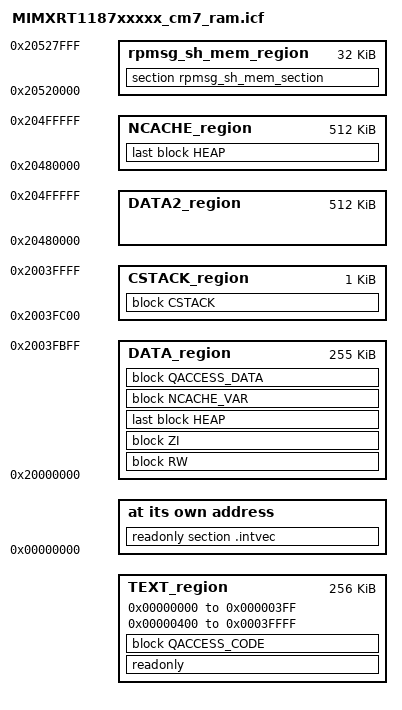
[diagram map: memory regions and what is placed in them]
/*
** ###################################################################
**     Processors:          MIMXRT1187CVM8B_cm7
**
**     Compiler:            IAR ANSI C/C++ Compiler for ARM
**     Reference manual:    IMXRT1180RM, Rev 1, 02/2021
**     Version:             rev. 1.0, 2020-12-29
**     Build:               b210402
**
**     Abstract:
**         Linker file for the IAR ANSI C/C++ Compiler for ARM
**
**     Copyright 2016 Freescale Semiconductor, Inc.
**     Copyright 2016-2021 NXP
**     All rights reserved.
**
**     SPDX-License-Identifier: BSD-3-Clause
**
**     http:                 www.nxp.com
**     mail:                 support@nxp.com
**
** ###################################################################
*/

define symbol vector_table_size        = 0x00000400;

define symbol m_itcm_start             = 0x00000000;
define symbol m_itcm_size              = 0x00040000;

define symbol m_dtcm_start             = 0x20000000;
define symbol m_dtcm_size              = 0x00040000;

define symbol m_ocram1_start           = 0x20480000;
define symbol m_ocram1_size            = 0x00080000;

define symbol m_ocram2_start           = 0x20500000;
define symbol m_ocram2_size            = 0x00020000;

if (isdefinedsymbol(__use_shmem__)) {
  define exported symbol rpmsg_sh_mem_start      = 0x20520000;
  define exported symbol rpmsg_sh_mem_end        = 0x20527FFF;

  define exported symbol __RPMSG_SH_MEM_START    = rpmsg_sh_mem_start;
  define exported symbol __RPMSG_SH_MEM_SIZE     = rpmsg_sh_mem_end - rpmsg_sh_mem_start + 1;
}

/* code & data allocation */
define symbol m_interrupts_start       = m_itcm_start;
define symbol m_interrupts_end         = m_itcm_start + vector_table_size -1;

define symbol m_text_start             = m_itcm_start + vector_table_size;
define symbol m_text_end               = m_itcm_start + m_itcm_size - 1;

define symbol m_data_start             = m_dtcm_start;
define symbol m_data_end               = m_dtcm_start + m_dtcm_size -1;

define symbol m_data2_start            = m_ocram1_start;
define symbol m_data2_end              = m_ocram1_start + m_ocram1_size -1;

define symbol m_ncache_start           = m_ocram1_start;
define symbol m_ncache_end             = m_ocram1_start + m_ocram1_size -1;

define exported symbol __NCACHE_REGION_START   = m_ncache_start;
define exported symbol __NCACHE_REGION_SIZE    = m_ncache_end - m_ncache_start + 1;

/* Sizes */
if (isdefinedsymbol(__stack_size__)) {
  define symbol __size_cstack__        = __stack_size__;
} else {
  define symbol __size_cstack__        = 0x0400;
}

if (isdefinedsymbol(__heap_size__)) {
  define symbol __size_heap__          = __heap_size__;
} else {
  define symbol __size_heap__          = 0x0400;
}

define exported symbol __VECTOR_TABLE          = m_interrupts_start;
define exported symbol __VECTOR_RAM            = m_interrupts_start;
define exported symbol __RAM_VECTOR_TABLE_SIZE = 0x0;

define memory mem with size = 4G;
define region TEXT_region = mem:[from m_interrupts_start to m_interrupts_end]
                          | mem:[from m_text_start to m_text_end];
define region DATA_region = mem:[from m_data_start to m_data_end-__size_cstack__];
define region DATA2_region = mem:[from m_data2_start to m_data2_end];
define region CSTACK_region = mem:[from m_data_end-__size_cstack__+1 to m_data_end];
define region NCACHE_region = mem:[from m_ncache_start to m_ncache_end];
if (isdefinedsymbol(__use_shmem__)) {
  define region rpmsg_sh_mem_region     = mem:[from rpmsg_sh_mem_start to rpmsg_sh_mem_end];
}

define block RW        { readwrite };
define block ZI        { zi };
define block CSTACK    with alignment = 8, size = __size_cstack__   { };
define block HEAP      with alignment = 8, size = __size_heap__     { };
define block NCACHE_VAR    { section NonCacheable , section NonCacheable.init };
define block QACCESS_CODE  { section CodeQuickAccess };
define block QACCESS_DATA  { section DataQuickAccess };

initialize by copy { readwrite, section .textrw, section CodeQuickAccess, section DataQuickAccess };
do not initialize  { section .noinit };
if (isdefinedsymbol(__use_shmem__)) {
  do not initialize  { section rpmsg_sh_mem_section };
}

place at address mem: m_interrupts_start    { readonly section .intvec };

place in TEXT_region                        { readonly };
place in DATA_region                        { block RW };
place in DATA_region                        { block ZI };
if (isdefinedsymbol(__heap_noncacheable__)) {
  place in NCACHE_region                    { last block HEAP };
} else {
  place in DATA_region                      { last block HEAP };
}
place in CSTACK_region                      { block CSTACK };
place in DATA_region                        { block NCACHE_VAR };
place in TEXT_region                        { block QACCESS_CODE };
place in DATA_region                        { block QACCESS_DATA };
if (isdefinedsymbol(__use_shmem__)) {
  place in rpmsg_sh_mem_region                { section rpmsg_sh_mem_section };
}
